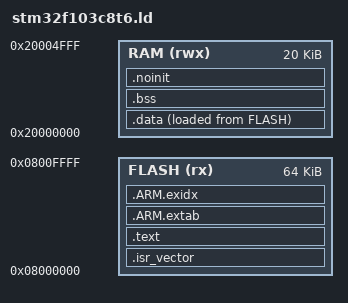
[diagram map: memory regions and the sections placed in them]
ENTRY(Reset_Handler)

MEMORY
{
    FLASH (rx)  : ORIGIN = 0x08000000, LENGTH = 64K
    RAM   (rwx) : ORIGIN = 0x20000000, LENGTH = 20K
}

_estack = ORIGIN(RAM) + LENGTH(RAM);
_Min_Stack_Size = 0x400;

SECTIONS
{
    .isr_vector :
    {
        . = ALIGN(4);
        KEEP(*(.isr_vector))
        . = ALIGN(4);
    } > FLASH

    .text :
    {
        . = ALIGN(4);
        *(.text)
        *(.text*)
        *(.rodata)
        *(.rodata*)
        . = ALIGN(4);
        _etext = .;
    } > FLASH

    .ARM.extab :
    {
        *(.ARM.extab*)
    } > FLASH

    .ARM.exidx :
    {
        __exidx_start = .;
        *(.ARM.exidx*)
        __exidx_end = .;
    } > FLASH

    _sidata = LOADADDR(.data);

    .data :
    {
        . = ALIGN(4);
        _sdata = .;
        *(.data)
        *(.data*)
        . = ALIGN(4);
        _edata = .;
    } > RAM AT > FLASH

    .bss (NOLOAD) :
    {
        . = ALIGN(4);
        _sbss = .;
        *(.bss)
        *(.bss*)
        *(COMMON)
        . = ALIGN(4);
        _ebss = .;
    } > RAM

    .noinit (NOLOAD) :
    {
        . = ALIGN(4);
        *(.noinit)
        *(.noinit*)
        . = ALIGN(4);
    } > RAM

    _end = .;

    /DISCARD/ :
    {
        *(.comment)
        *(.note*)
    }
}

ASSERT((_end + _Min_Stack_Size) <= _estack,
       "RAM overflow: static data leaves less than the reserved stack size")
